# M3HQ register map
File version: 0.1
Registers are 32-bit, read-write, reset 0x0 unless marked. A register's access mark holds for its fields unless they carry their own. Offsets are from the block's base; [hi:lo] are bit positions; {n}, {i} and the like mark numbered series.

## I2CS — I2C Wakeup control register
Base 0x4003E800
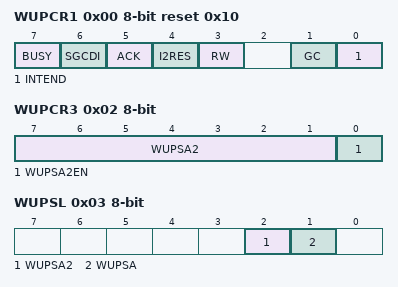
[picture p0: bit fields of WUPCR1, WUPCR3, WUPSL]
0x00 WUPCR1 8-bit reset 0x10 — I2C Wakeup control register1
  [7] BUSY ro, [6] SGCDI, [5] ACK, [4] I2RES, [3] RW ro, [1] GC ro, [0] INTEND
0x01 WUPCR2 8-bit — I2C Wakeup control register2
  [7:1] WUPSA1
0x02 WUPCR3 8-bit — I2C Wakeup control register3
  [7:1] WUPSA2, [0] WUPSA2EN
0x03 WUPSL 8-bit ro — I2C Wakeup Status register
  [2] WUPSA2, [1] WUPSA

## LVD — LVD0
Base 0x4003EC00
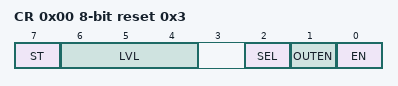
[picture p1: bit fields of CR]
0x00 CR 8-bit reset 0x3 — LVD Control register
  [7] ST ro, [6:4] LVL, [2] SEL, [1] OUTEN, [0] EN

## DMAA — DMA Controller
Base 0x4004C000
Same registers: DMAB 0x4004D000
0x00 STATUS ro reset 0x101F0000 — DMA Status Register
  [0] MASTER_ENABLE
0x04 CFG wo — DMA Configuration Register
  [0] MASTER_ENABLE
0x08 CTRLBASEPTR — DMA Control Data Base Pointer Register
  [31:10] CTRL_BASE_PTR
0x0C ALTCTRLBASEPTR ro — DMA Channel Alternate Control Data Base Pointer Register
  [31:0] ALT_CTRL_BASE_PTR
0x14 CHNLSWREQUEST wo — DMA Channel Software Request Register
  [31:0] CHNL_SW_REQUEST
0x18 CHNLUSEBURSTSET — DMA Channel Useburst Set Register
  [31:0] CHNL_USEBURST_SET
0x1C CHNLUSEBURSTCLR wo — DMA Channel Useburst Clear Register
  [31:0] CHNL_USEBURST_CLR
0x20 CHNLREQMASKSET — DMA Channel Request Mask Set Register
  [31:0] CHNL_REQ_MASK_SET
0x24 CHNLREQMASKCLR wo — DMA Channel Request Mask Clear Register
  [31:0] CHNL_REQ_MASK_CLR
0x28 CHNLENABLESET — DMA Channel Enable Set Register
  [31:0] CHNL_ENABLE_SET
0x2C CHNLENABLECLR wo — DMA Channel Enable Clear Register
  [31:0] CHNL_ENABLE_CLR
0x30 CHNLPRIALTSET — DMA Channel Primary-Alternate Set Register
  [31:0] CHNL_PRI_ALT_SET
0x34 CHNLPRIALTCLR wo — DMA Channel Primary-Alternate Clear Register
  [31:0] CHNL_PRI_ALT_CLR
0x38 CHNLPRIORITYSET — DMA Channel Priority Set Register
  [31:0] CHNL_PRIORITY_SET
0x3C CHNLPRIORITYCLR wo — DMA Channel Priority Clear Register
  [31:0] CHNL_PRIORITY_CLR
0x4C ERRCLR — DMA Bus Error Clear Register
  [0] ERR_CLR

## DA0 — Digital analog converter (DAC)
Base 0x40054000
Same registers: DA1 0x40055000
0x00 CTL — DAC Control Register
  [0] EN
0x04 REG — DAC output Register
  [7:0] DAC

## TSPI0 — Serial Interface (TSPI)
Base 0x40098000
Same registers: TSPI1 0x40099000, TSPI2 0x4009A000, TSPI3 0x4009B000, TSPI4 0x4009C000
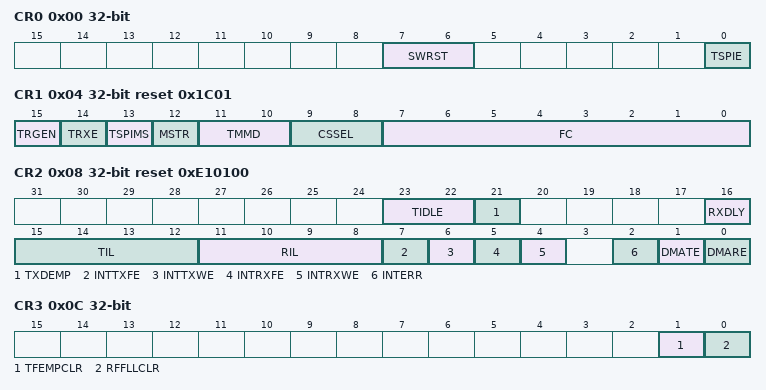
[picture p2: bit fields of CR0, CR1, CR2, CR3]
0x00 CR0 — TSPI Control Register 0
  [7:6] SWRST wo, [0] TSPIE
0x04 CR1 reset 0x1C01 — TSPI Control Register 1
  [15] TRGEN, [14] TRXE, [13] TSPIMS, [12] MSTR, [11:10] TMMD, [9:8] CSSEL, [7:0] FC
0x08 CR2 reset 0xE10100 — TSPI Control Register 2
  [23:22] TIDLE, [21] TXDEMP, [16] RXDLY, [15:12] TIL, [11:8] RIL, [7] INTTXFE, [6] INTTXWE, [5] INTRXFE, [4] INTRXWE, [2] INTERR, [1] DMATE, [0] DMARE
0x0C CR3 — TSPI Control Register 3
  [1] TFEMPCLR wo, [0] RFFLLCLR wo
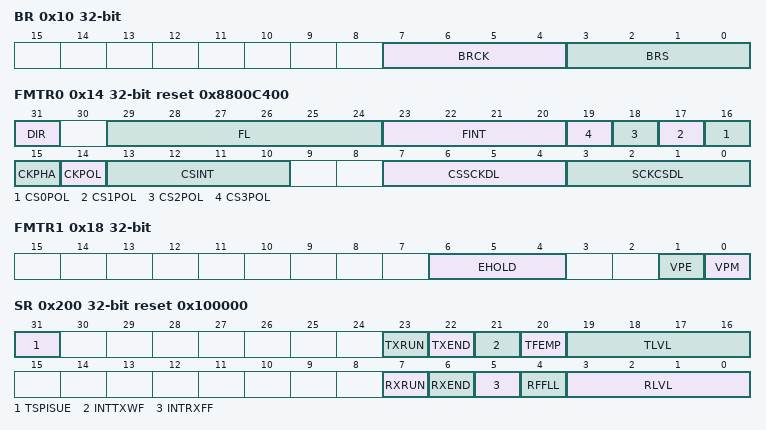
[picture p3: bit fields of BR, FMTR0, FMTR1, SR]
0x10 BR — TSPI Baud Rate Generator Control Register
  [7:4] BRCK, [3:0] BRS
0x14 FMTR0 reset 0x8800C400 — TSPI Format Control Register 0
  [31] DIR, [29:24] FL, [23:20] FINT, [n+16] CS{n}POL (n=0..3), [15] CKPHA, [14] CKPOL, [13:10] CSINT, [7:4] CSSCKDL, [3:0] SCKCSDL
0x18 FMTR1 — TSPI Format Control Register 1
  [6:4] EHOLD, [1] VPE, [0] VPM
0x100 DR — TSPI Data Register
  [31:0] TSPIDR
0x200 SR reset 0x100000 — TSPI Status Register
  [31] TSPISUE ro, [23] TXRUN ro, [22] TXEND, [21] INTTXWF, [20] TFEMP ro, [19:16] TLVL ro, [7] RXRUN ro, [6] RXEND, [5] INTRXFF, [4] RFFLL ro, [3:0] RLVL ro
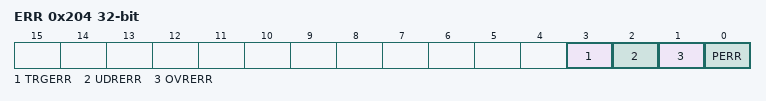
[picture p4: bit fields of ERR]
0x204 ERR — TSPI Parity Error Flag Register
  [3] TRGERR, [2] UDRERR, [1] OVRERR, [0] PERR

## I2C0 — I2C
Base 0x400A0000
Same registers: I2C1 0x400A1000, I2C2 0x400A2000, I2C3 0x400A3000
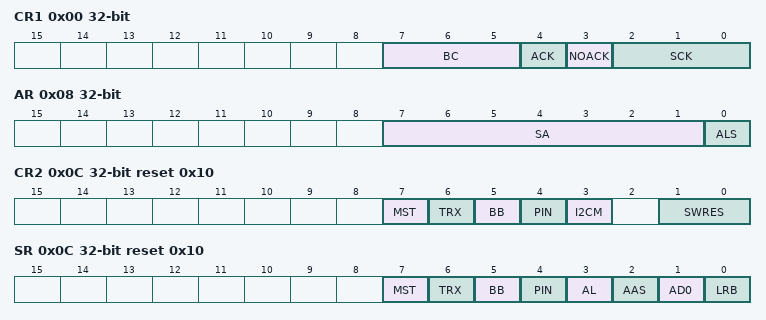
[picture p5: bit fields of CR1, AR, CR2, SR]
0x00 CR1 — I2C Control Register 1
  [7:5] BC, [4] ACK, [3] NOACK, [2:0] SCK
0x04 DBR — I2C Data Buffer Register
  [7:0] DB
0x08 AR — I2C Bus address Register
  [7:1] SA, [0] ALS
0x0C CR2 wo reset 0x10 — I2C Control Register 2
  [7] MST, [6] TRX, [5] BB, [4] PIN, [3] I2CM, [1:0] SWRES
0x0C SR ro reset 0x10 — I2C Status Register
  [7] MST, [6] TRX, [5] BB, [4] PIN, [3] AL, [2] AAS, [1] AD0, [0] LRB
0x10 PRS reset 0x1 — I2C Prescaler clcok setting Register
  [4:0] PRSCK
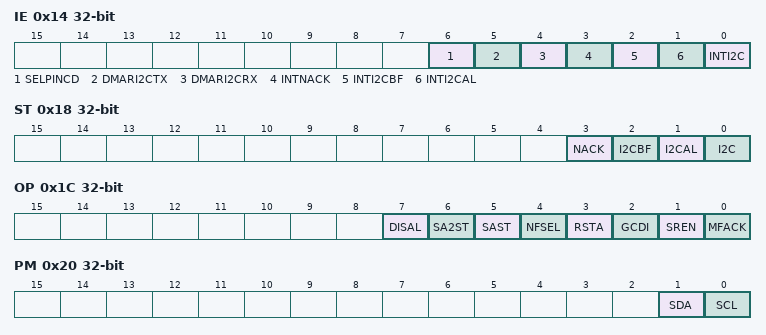
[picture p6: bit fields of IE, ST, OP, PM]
0x14 IE — I2C Interrupt Enable Register
  [6] SELPINCD, [5] DMARI2CTX, [4] DMARI2CRX, [3] INTNACK, [2] INTI2CBF, [1] INTI2CAL, [0] INTI2C
0x18 ST — I2C Interrupt Register
  [3] NACK, [2] I2CBF, [1] I2CAL, [0] I2C
0x1C OP — I2C Optiononal Function register
  [7] DISAL, [6] SA2ST ro, [5] SAST ro, [4] NFSEL, [3] RSTA, [2] GCDI, [1] SREN, [0] MFACK
0x20 PM ro — I2C Bus Monitor register
  [1] SDA, [0] SCL
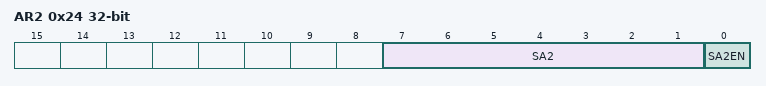
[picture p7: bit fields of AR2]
0x24 AR2 — I2C Second Slave address register
  [7:1] SA2, [0] SA2EN
